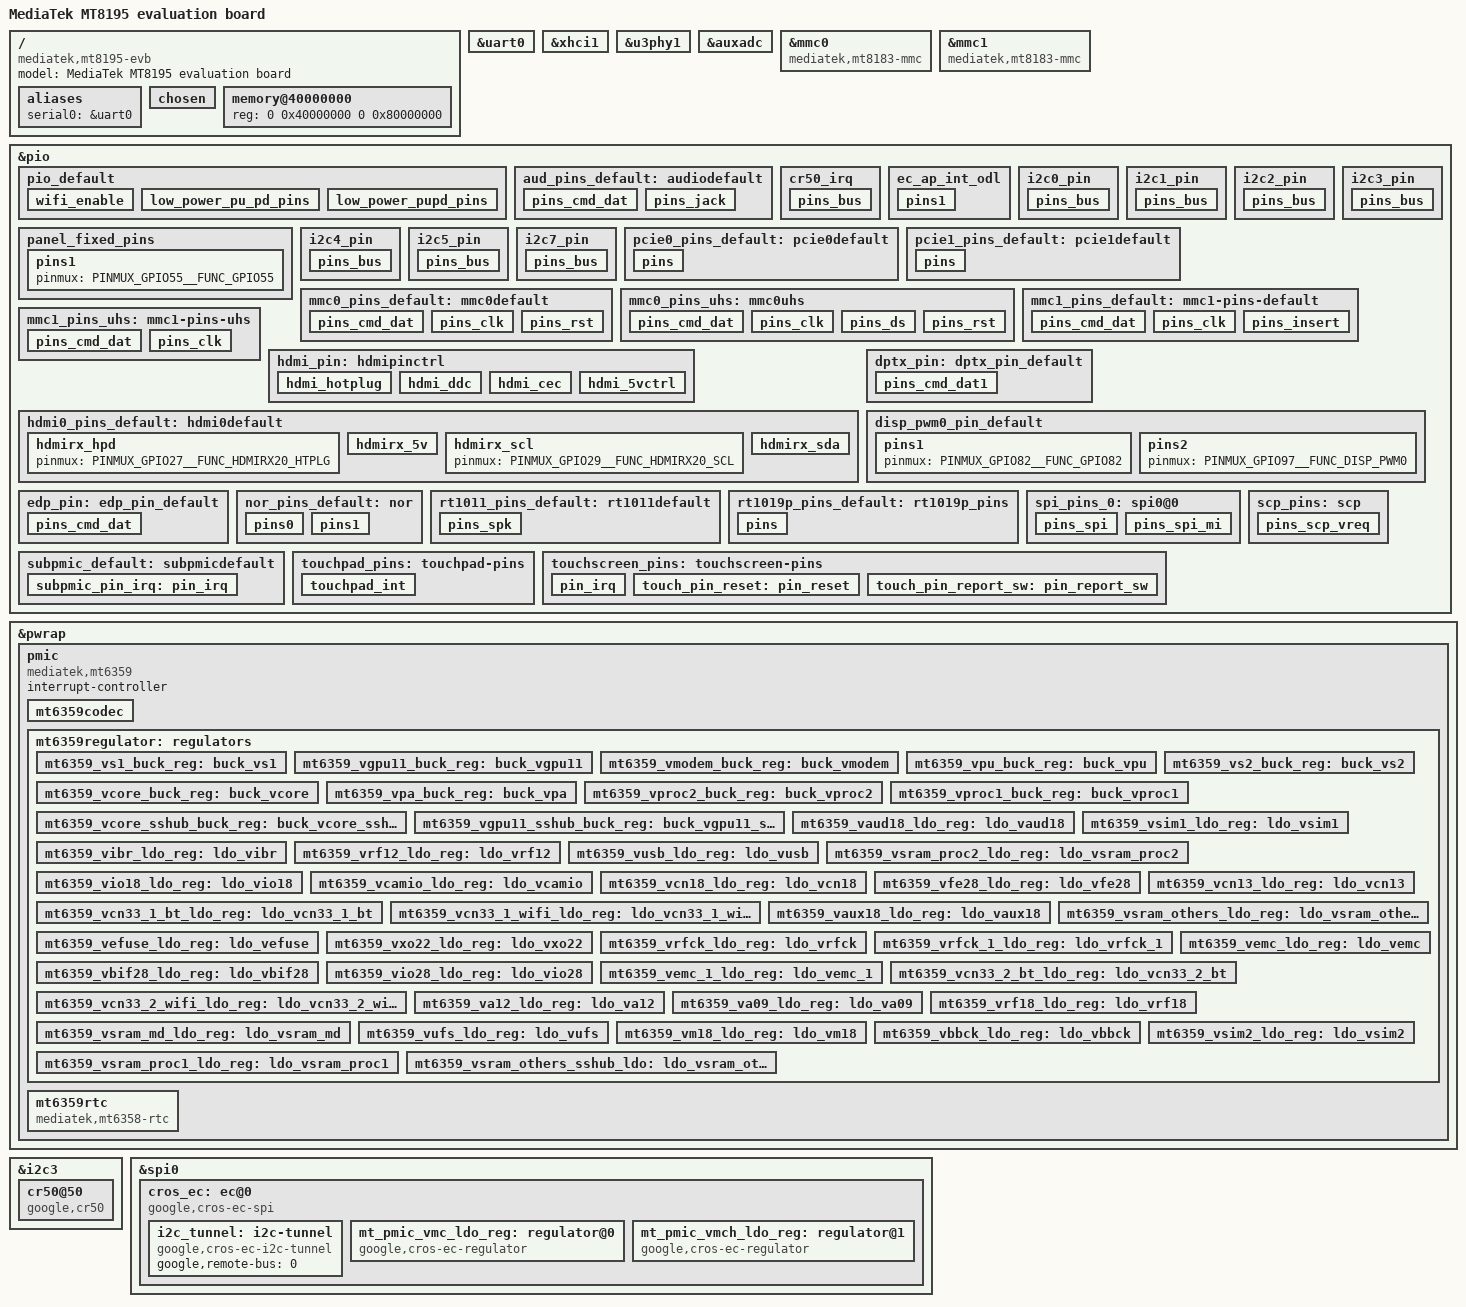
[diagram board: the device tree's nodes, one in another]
// SPDX-License-Identifier: (GPL-2.0 OR MIT)
/*
 * Copyright (C) 2021 MediaTek Inc.
 * Author: Seiya Wang <seiya.wang@mediatek.com>
 */
/dts-v1/;
#include <dt-bindings/gpio/gpio.h>
#include "mt8195.dtsi"

/ {
	model = "MediaTek MT8195 evaluation board";
	compatible = "mediatek,mt8195-evb", "mediatek,mt8195";

	aliases {
		serial0 = &uart0;
	};

	chosen {
		stdout-path = "serial0:115200n8";
		bootargs = "earlycon earlyprintk";
	};

	memory@40000000 {
		device_type = "memory";
		reg = <0 0x40000000 0 0x80000000>;
	};
};

&uart0 {
	status = "okay";
};

&xhci1 {
	status = "okay";
};

&u3phy1 {
	status = "okay";
};

&auxadc {
	status = "okay";
};



&mmc0 {
	/* Note: fixup for bad compatible on mt8195.dtsi */
	compatible = "mediatek,mt8183-mmc";
};

&mmc1 {
	/* Note: fixup for bad compatible on mt8195.dtsi */
	compatible = "mediatek,mt8183-mmc";
};

&mmc0 {
	status = "okay";
	pinctrl-names = "default", "state_uhs";
	pinctrl-0 = <&mmc0_pins_default>;
	pinctrl-1 = <&mmc0_pins_uhs>;
	bus-width = <8>;
	max-frequency = <200000000>;
	cap-mmc-highspeed;
	mmc-hs200-1_8v;
	mmc-hs400-1_8v;
	cap-mmc-hw-reset;
	no-sdio;
	no-sd;
	hs400-ds-delay = <0x14c11>;
	vmmc-supply = <&mt6359_vemc_1_ldo_reg>;
	vqmmc-supply = <&mt6359_vufs_ldo_reg>;
	non-removable;
};

&mmc1 {
	status = "okay";
	pinctrl-names = "default", "state_uhs";
	pinctrl-0 = <&mmc1_pins_default>;
	pinctrl-1 = <&mmc1_pins_uhs>;
	bus-width = <4>;
	max-frequency = <200000000>;
	cap-sd-highspeed;
	sd-uhs-sdr50;
	sd-uhs-sdr104;
	no-mmc;
	no-sdio;
	cd-gpios = <&pio 54 GPIO_ACTIVE_LOW>;
	vmmc-supply = <&mt_pmic_vmch_ldo_reg>;
	vqmmc-supply = <&mt_pmic_vmc_ldo_reg>;
};

&pio {
	pinctrl-names = "default";
	pinctrl-0 = <&pio_default>;
	/* 144 lines */
	gpio-line-names =
		"I2S_SPKR_MCLK",
		"I2S_SPKR_DATAIN",
		"I2S_SPKR_LRCK",
		"I2S_SPKR_BCLK",
		"EC_AP_INT_ODL",
		/*
		 * AP_FLASH_WP_L is crossystem ABI. Schematics
		 * call it AP_FLASH_WP_ODL.
		 */
		"AP_FLASH_WP_L",
		"TCHPAD_INT_ODL",
		"EDP_HPD_1V8",
		"AP_I2C_CAM_SDA",
		"AP_I2C_CAM_SCL",
		"AP_I2C_TCHPAD_SDA_1V8",
		"AP_I2C_TCHPAD_SCL_1V8",
		"AP_I2C_AUD_SDA",
		"AP_I2C_AUD_SCL",
		"AP_I2C_TPM_SDA_1V8",
		"AP_I2C_TPM_SCL_1V8",
		"AP_I2C_TCHSCR_SDA_1V8",
		"AP_I2C_TCHSCR_SCL_1V8",
		"EC_AP_HPD_OD",
		"",
		"PCIE_NVME_RST_L",
		"PCIE_NVME_CLKREQ_ODL",
		"PCIE_RST_1V8_L",
		"PCIE_CLKREQ_1V8_ODL",
		"PCIE_WAKE_1V8_ODL",
		"CLK_24M_CAM0",
		"CAM1_SEN_EN",
		"AP_I2C_PWR_SCL_1V8",
		"AP_I2C_PWR_SDA_1V8",
		"AP_I2C_MISC_SCL",
		"AP_I2C_MISC_SDA",
		"EN_PP5000_HDMI_X",
		"AP_HDMITX_HTPLG",
		"",
		"AP_HDMITX_SCL_1V8",
		"AP_HDMITX_SDA_1V8",
		"AP_RTC_CLK32K",
		"AP_EC_WATCHDOG_L",
		"SRCLKENA0",
		"SRCLKENA1",
		"PWRAP_SPI0_CS_L",
		"PWRAP_SPI0_CK",
		"PWRAP_SPI0_MOSI",
		"PWRAP_SPI0_MISO",
		"SPMI_SCL",
		"SPMI_SDA",
		"",
		"",
		"",
		"I2S_HP_DATAIN",
		"I2S_HP_MCLK",
		"I2S_HP_BCK",
		"I2S_HP_LRCK",
		"I2S_HP_DATAOUT",
		"SD_CD_ODL",
		"EN_PP3300_DISP_X",
		"TCHSCR_RST_1V8_L",
		"TCHSCR_REPORT_DISABLE",
		"EN_PP3300_WLAN_X",
		"BT_KILL_1V8_L",
		"I2S_SPKR_DATAOUT",
		"WIFI_KILL_1V8_L",
		"BEEP_ON",
		"SCP_I2C_SENSOR_SCL_1V8",
		"SCP_I2C_SENSOR_SDA_1V8",
		"",
		"",
		"",
		"",
		"AUD_CLK_MOSI",
		"AUD_SYNC_MOSI",
		"AUD_DAT_MOSI0",
		"AUD_DAT_MOSI1",
		"AUD_DAT_MISO0",
		"AUD_DAT_MISO1",
		"AUD_DAT_MISO2",
		"SCP_VREQ_VAO",
		"AP_SPI_GSC_TPM_CLK",
		"AP_SPI_GSC_TPM_MOSI",
		"AP_SPI_GSC_TPM_CS_L",
		"AP_SPI_GSC_TPM_MISO",
		"EN_PP1000_CAM_X",
		"AP_EDP_BKLTEN",
		"",
		"USB3_HUB_RST_L",
		"",
		"WLAN_ALERT_ODL",
		"EC_IN_RW_ODL",
		"GSC_AP_INT_ODL",
		"HP_INT_ODL",
		"CAM0_RST_L",
		"CAM1_RST_L",
		"TCHSCR_INT_1V8_L",
		"CAM1_DET_L",
		"RST_ALC1011_L",
		"",
		"",
		"BL_PWM_1V8",
		"UART_AP_TX_DBG_RX",
		"UART_DBG_TX_AP_RX",
		"EN_SPKR",
		"AP_EC_WARM_RST_REQ",
		"UART_SCP_TX_DBGCON_RX",
		"UART_DBGCON_TX_SCP_RX",
		"",
		"",
		"KPCOL0",
		"",
		"MT6315_GPU_INT",
		"MT6315_PROC_BC_INT",
		"SD_CMD",
		"SD_CLK",
		"SD_DAT0",
		"SD_DAT1",
		"SD_DAT2",
		"SD_DAT3",
		"EMMC_DAT7",
		"EMMC_DAT6",
		"EMMC_DAT5",
		"EMMC_DAT4",
		"EMMC_RSTB",
		"EMMC_CMD",
		"EMMC_CLK",
		"EMMC_DAT3",
		"EMMC_DAT2",
		"EMMC_DAT1",
		"EMMC_DAT0",
		"EMMC_DSL",
		"",
		"",
		"MT6360_INT_ODL",
		"SCP_JTAG0_TRSTN",
		"AP_SPI_EC_CS_L",
		"AP_SPI_EC_CLK",
		"AP_SPI_EC_MOSI",
		"AP_SPI_EC_MISO",
		"SCP_JTAG0_TMS",
		"SCP_JTAG0_TCK",
		"SCP_JTAG0_TDO",
		"SCP_JTAG0_TDI",
		"AP_SPI_FLASH_CS_L",
		"AP_SPI_FLASH_CLK",
		"AP_SPI_FLASH_MOSI",
		"AP_SPI_FLASH_MISO";

	pio_default: pio_default {
		wifi_enable {
			pinmux = <PINMUX_GPIO58__FUNC_GPIO58>;
			output-high;
			drive-strength = <MTK_DRIVE_14mA>;
		};
		low_power_pu_pd_pins {
			pinmux = <PINMUX_GPIO8__FUNC_GPIO8>,
				 <PINMUX_GPIO9__FUNC_GPIO9>,
				 <PINMUX_GPIO19__FUNC_GPIO19>,
				 <PINMUX_GPIO20__FUNC_GPIO20>,
				 <PINMUX_GPIO21__FUNC_GPIO21>,
				 <PINMUX_GPIO25__FUNC_GPIO25>,
				 <PINMUX_GPIO26__FUNC_GPIO26>,
				 <PINMUX_GPIO46__FUNC_GPIO46>,
				 <PINMUX_GPIO47__FUNC_GPIO47>,
				 <PINMUX_GPIO48__FUNC_GPIO48>,
				 <PINMUX_GPIO65__FUNC_GPIO65>,
				 <PINMUX_GPIO66__FUNC_GPIO66>,
				 <PINMUX_GPIO67__FUNC_GPIO67>,
				 <PINMUX_GPIO68__FUNC_GPIO68>,
				 <PINMUX_GPIO128__FUNC_GPIO128>,
				 <PINMUX_GPIO129__FUNC_GPIO129>;
			input-enable;
			bias-pull-down;
		};
		low_power_pupd_pins {
			pinmux = <PINMUX_GPIO77__FUNC_GPIO77>,
				 <PINMUX_GPIO78__FUNC_GPIO78>,
				 <PINMUX_GPIO79__FUNC_GPIO79>,
				 <PINMUX_GPIO80__FUNC_GPIO80>,
				 <PINMUX_GPIO83__FUNC_GPIO83>,
				 <PINMUX_GPIO85__FUNC_GPIO85>,
				 <PINMUX_GPIO90__FUNC_GPIO90>,
				 <PINMUX_GPIO91__FUNC_GPIO91>,
				 <PINMUX_GPIO93__FUNC_GPIO93>,
				 <PINMUX_GPIO94__FUNC_GPIO94>,
				 <PINMUX_GPIO95__FUNC_GPIO95>,
				 <PINMUX_GPIO96__FUNC_GPIO96>,
				 <PINMUX_GPIO104__FUNC_GPIO104>,
				 <PINMUX_GPIO105__FUNC_GPIO105>,
				 <PINMUX_GPIO107__FUNC_GPIO107>;
			input-enable;
			bias-pull-down = <MTK_PUPD_SET_R1R0_01>;
		};
	};
	aud_pins_default: audiodefault {
		pins_cmd_dat {
		    pinmux = <PINMUX_GPIO69__FUNC_AUD_CLK_MOSI>,
			     <PINMUX_GPIO70__FUNC_AUD_SYNC_MOSI>,
			     <PINMUX_GPIO71__FUNC_AUD_DAT_MOSI0>,
			     <PINMUX_GPIO72__FUNC_AUD_DAT_MOSI1>,
			     <PINMUX_GPIO73__FUNC_AUD_DAT_MISO0>,
			     <PINMUX_GPIO74__FUNC_AUD_DAT_MISO1>,
			     <PINMUX_GPIO75__FUNC_AUD_DAT_MISO2>,
			     <PINMUX_GPIO0__FUNC_TDMIN_MCK>,
			     <PINMUX_GPIO1__FUNC_TDMIN_DI>,
			     <PINMUX_GPIO2__FUNC_TDMIN_LRCK>,
			     <PINMUX_GPIO3__FUNC_TDMIN_BCK>,
			     <PINMUX_GPIO60__FUNC_I2SO2_D0>,
			     <PINMUX_GPIO49__FUNC_I2SIN_D0>,
			     <PINMUX_GPIO50__FUNC_I2SO1_MCK>,
			     <PINMUX_GPIO51__FUNC_I2SO1_BCK>,
			     <PINMUX_GPIO52__FUNC_I2SO1_WS>,
			     <PINMUX_GPIO53__FUNC_I2SO1_D0>;
		};
		pins_jack {
			pinmux = <PINMUX_GPIO89__FUNC_GPIO89>;
			input-enable;
			bias-pull-up = <MTK_PUPD_SET_R1R0_01>;
		};
	};
	cr50_irq: cr50_irq {
		pins_bus {
			pinmux = <PINMUX_GPIO88__FUNC_GPIO88>;
			input-enable;
		};
	};
	ec_ap_int_odl: ec_ap_int_odl {
		pins1 {
			pinmux = <PINMUX_GPIO4__FUNC_GPIO4>;
			input-enable;
			bias-pull-up = <MTK_PUPD_SET_R1R0_01>;
		};
	};
	i2c0_pin: i2c0_pin {
		pins_bus {
			pinmux = <PINMUX_GPIO8__FUNC_SDA0>,
				 <PINMUX_GPIO9__FUNC_SCL0>;
			bias-disable;
			mediatek,drive-strength-adv = <7>;
		};
	};
	i2c1_pin: i2c1_pin {
		pins_bus {
			pinmux = <PINMUX_GPIO10__FUNC_SDA1>,
				 <PINMUX_GPIO11__FUNC_SCL1>;
			bias-pull-up;
			mediatek,rsel = <7>;
			mediatek,drive-strength-adv = <7>;
		};
	};
	i2c2_pin: i2c2_pin {
		pins_bus {
			pinmux = <PINMUX_GPIO12__FUNC_SDA2>,
				 <PINMUX_GPIO13__FUNC_SCL2>;
			bias-disable;
			mediatek,drive-strength-adv = <7>;
		};
	};
	panel_fixed_pins: panel_fixed_pins {
		pins1 {
			pinmux = <PINMUX_GPIO55__FUNC_GPIO55>;
		};
	};
	i2c3_pin: i2c3_pin {
		pins_bus {
			pinmux = <PINMUX_GPIO14__FUNC_SDA3>,
				 <PINMUX_GPIO15__FUNC_SCL3>;
			bias-pull-up;
			mediatek,rsel = <7>;
			mediatek,drive-strength-adv = <7>;
		};
	};
	i2c4_pin: i2c4_pin {
		pins_bus {
			pinmux = <PINMUX_GPIO16__FUNC_SDA4>,
				 <PINMUX_GPIO17__FUNC_SCL4>;
			bias-pull-up;
			mediatek,rsel = <7>;
			mediatek,drive-strength-adv = <0>;
			drive-strength = <MTK_DRIVE_4mA>;
		};
	};
	i2c5_pin: i2c5_pin {
		pins_bus {
			pinmux = <PINMUX_GPIO29__FUNC_SCL5>,
				 <PINMUX_GPIO30__FUNC_SDA5>;
			bias-disable;
			mediatek,drive-strength-adv = <7>;
		};
	};
	i2c7_pin: i2c7_pin {
		pins_bus {
			pinmux = <PINMUX_GPIO27__FUNC_SCL7>,
				 <PINMUX_GPIO28__FUNC_SDA7>;
			bias-disable;
		};
	};
	pcie0_pins_default: pcie0default {
		pins {
			pinmux = <PINMUX_GPIO19__FUNC_WAKEN>,
				 <PINMUX_GPIO20__FUNC_PERSTN>,
				 <PINMUX_GPIO21__FUNC_CLKREQN>;
				 bias-pull-up;
		};
	};
	pcie1_pins_default: pcie1default {
		pins {
			pinmux = <PINMUX_GPIO22__FUNC_PERSTN_1>,
				 <PINMUX_GPIO23__FUNC_CLKREQN_1>,
				 <PINMUX_GPIO24__FUNC_WAKEN_1>;
				 bias-pull-up;
		};
	};
	mmc0_pins_default: mmc0default {
		pins_cmd_dat {
			pinmux = <PINMUX_GPIO126__FUNC_MSDC0_DAT0>,
				 <PINMUX_GPIO125__FUNC_MSDC0_DAT1>,
				 <PINMUX_GPIO124__FUNC_MSDC0_DAT2>,
				 <PINMUX_GPIO123__FUNC_MSDC0_DAT3>,
				 <PINMUX_GPIO119__FUNC_MSDC0_DAT4>,
				 <PINMUX_GPIO118__FUNC_MSDC0_DAT5>,
				 <PINMUX_GPIO117__FUNC_MSDC0_DAT6>,
				 <PINMUX_GPIO116__FUNC_MSDC0_DAT7>,
				 <PINMUX_GPIO121__FUNC_MSDC0_CMD>;
			input-enable;
			drive-strength = <MTK_DRIVE_6mA>;
			bias-pull-up = <MTK_PUPD_SET_R1R0_01>;
		};
		pins_clk {
			pinmux = <PINMUX_GPIO122__FUNC_MSDC0_CLK>;
			drive-strength = <MTK_DRIVE_6mA>;
			bias-pull-down = <MTK_PUPD_SET_R1R0_10>;
		};
		pins_rst {
			pinmux = <PINMUX_GPIO120__FUNC_MSDC0_RSTB>;
			drive-strength = <MTK_DRIVE_6mA>;
			bias-pull-up = <MTK_PUPD_SET_R1R0_01>;
		};
	};
	mmc0_pins_uhs: mmc0uhs{
		pins_cmd_dat {
			pinmux = <PINMUX_GPIO126__FUNC_MSDC0_DAT0>,
				 <PINMUX_GPIO125__FUNC_MSDC0_DAT1>,
				 <PINMUX_GPIO124__FUNC_MSDC0_DAT2>,
				 <PINMUX_GPIO123__FUNC_MSDC0_DAT3>,
				 <PINMUX_GPIO119__FUNC_MSDC0_DAT4>,
				 <PINMUX_GPIO118__FUNC_MSDC0_DAT5>,
				 <PINMUX_GPIO117__FUNC_MSDC0_DAT6>,
				 <PINMUX_GPIO116__FUNC_MSDC0_DAT7>,
				 <PINMUX_GPIO121__FUNC_MSDC0_CMD>;
			input-enable;
			drive-strength = <MTK_DRIVE_8mA>;
			bias-pull-up = <MTK_PUPD_SET_R1R0_01>;
		};
		pins_clk {
			pinmux = <PINMUX_GPIO122__FUNC_MSDC0_CLK>;
			drive-strength = <MTK_DRIVE_8mA>;
			bias-pull-down = <MTK_PUPD_SET_R1R0_10>;
		};
		pins_ds {
			pinmux = <PINMUX_GPIO127__FUNC_MSDC0_DSL>;
			drive-strength = <MTK_DRIVE_8mA>;
			bias-pull-down = <MTK_PUPD_SET_R1R0_10>;
		};
		pins_rst {
			pinmux = <PINMUX_GPIO120__FUNC_MSDC0_RSTB>;
			drive-strength = <MTK_DRIVE_8mA>;
			bias-pull-up = <MTK_PUPD_SET_R1R0_01>;
		};
	};
	mmc1_pins_default: mmc1-pins-default {
		pins_cmd_dat {
			pinmux = <PINMUX_GPIO110__FUNC_MSDC1_CMD>,
				 <PINMUX_GPIO112__FUNC_MSDC1_DAT0>,
				 <PINMUX_GPIO113__FUNC_MSDC1_DAT1>,
				 <PINMUX_GPIO114__FUNC_MSDC1_DAT2>,
				 <PINMUX_GPIO115__FUNC_MSDC1_DAT3>;
			input-enable;
			drive-strength = <MTK_DRIVE_8mA>;
			bias-pull-up = <MTK_PUPD_SET_R1R0_01>;
		};
		pins_clk {
			pinmux = <PINMUX_GPIO111__FUNC_MSDC1_CLK>;
			drive-strength = <MTK_DRIVE_8mA>;
			bias-pull-down = <MTK_PUPD_SET_R1R0_10>;
		};
		pins_insert {
			pinmux = <PINMUX_GPIO54__FUNC_GPIO54>;
			bias-pull-up;
		};
	};
	mmc1_pins_uhs: mmc1-pins-uhs {
		pins_cmd_dat {
			pinmux = <PINMUX_GPIO110__FUNC_MSDC1_CMD>,
				 <PINMUX_GPIO112__FUNC_MSDC1_DAT0>,
				 <PINMUX_GPIO113__FUNC_MSDC1_DAT1>,
				 <PINMUX_GPIO114__FUNC_MSDC1_DAT2>,
				 <PINMUX_GPIO115__FUNC_MSDC1_DAT3>;
			input-enable;
			drive-strength = <MTK_DRIVE_8mA>;
			bias-pull-up = <MTK_PUPD_SET_R1R0_01>;
		};
		pins_clk {
			pinmux = <PINMUX_GPIO111__FUNC_MSDC1_CLK>;
			drive-strength = <MTK_DRIVE_8mA>;
			bias-pull-down = <MTK_PUPD_SET_R1R0_10>;
		};
	};
	hdmi_pin: hdmipinctrl {
		hdmi_hotplug {
			pinmux = <PINMUX_GPIO32__FUNC_HDMITX20_HTPLG>;
			bias-disable;
			input-enable;
		};
		hdmi_ddc {
			pinmux = <PINMUX_GPIO34__FUNC_HDMITX20_SCL>,
				 <PINMUX_GPIO35__FUNC_HDMITX20_SDA>;
			mediatek,drive-strength-adv = <0>;
			drive-strength = <MTK_DRIVE_10mA>;
		};
		hdmi_cec {
			pinmux = <PINMUX_GPIO33__FUNC_HDMITX20_CEC>;
			bias-disable;
		};
		hdmi_5vctrl {
			pinmux = <PINMUX_GPIO31__FUNC_GPIO31>;
			slew-rate = <1>;
			output-high;
		};
	};
	hdmi0_pins_default: hdmi0default {
		hdmirx_hpd {
			pinmux = <PINMUX_GPIO27__FUNC_HDMIRX20_HTPLG>;
		};
		hdmirx_5v {
			pinmux = <PINMUX_GPIO28__FUNC_HDMIRX20_PWR5V>;
			bias-disable;
		};
		hdmirx_scl {
			pinmux = <PINMUX_GPIO29__FUNC_HDMIRX20_SCL>;
		};
		hdmirx_sda {
			pinmux = <PINMUX_GPIO30__FUNC_HDMIRX20_SDA>;
			mediatek,drive-strength-adv = <0>;
			drive-strength = <MTK_DRIVE_10mA>;
		};
	};
	dptx_pin: dptx_pin_default {
		pins_cmd_dat1 {
			pinmux = <PINMUX_GPIO18__FUNC_DP_TX_HPD>;
			bias-pull-up;
		};
	};
	disp_pwm0_pin_default: disp_pwm0_pin_default {
		pins1 {
			pinmux = <PINMUX_GPIO82__FUNC_GPIO82>;
		};
		pins2 {
			pinmux = <PINMUX_GPIO97__FUNC_DISP_PWM0>;
		};
	};
	edp_pin: edp_pin_default {
		pins_cmd_dat {
			pinmux = <PINMUX_GPIO7__FUNC_EDP_TX_HPD>;
			bias-pull-up;
		};
	};
	nor_pins_default: nor {
		pins0 {
			pinmux = <PINMUX_GPIO142__FUNC_SPINOR_IO0>,
				 <PINMUX_GPIO141__FUNC_SPINOR_CK>,
				 <PINMUX_GPIO143__FUNC_SPINOR_IO1>;
			drive-strength = <MTK_DRIVE_6mA>;
			bias-pull-down;
		};
		pins1 {
			pinmux = <PINMUX_GPIO140__FUNC_SPINOR_CS>;
			drive-strength = <MTK_DRIVE_6mA>;
			bias-pull-up;
		};
	};
	rt1011_pins_default: rt1011default {
		pins_spk {
			pinmux = <PINMUX_GPIO94__FUNC_GPIO94>,
			     <PINMUX_GPIO100__FUNC_GPIO100>;
			output-high;
		};
	};
	rt1019p_pins_default: rt1019p_pins {
		pins {
			pinmux = <PINMUX_GPIO100__FUNC_GPIO100>;
			output-low;
		};
	};
	spi_pins_0: spi0@0 {
		pins_spi {
			pinmux = <PINMUX_GPIO132__FUNC_SPIM0_CSB>,
				 <PINMUX_GPIO134__FUNC_SPIM0_MO>,
				 <PINMUX_GPIO133__FUNC_SPIM0_CLK>;
			bias-disable;
		};
		pins_spi_mi {
			pinmux = <PINMUX_GPIO135__FUNC_SPIM0_MI>;
			bias-pull-down;
		};
	};
	subpmic_default: subpmicdefault {
		subpmic_pin_irq: pin_irq {
			pinmux = <PINMUX_GPIO130__FUNC_GPIO130>;
			input-enable;
			bias-pull-up;
		};
	};
	touchpad_pins: touchpad-pins {
		touchpad_int {
			pinmux = <PINMUX_GPIO6__FUNC_GPIO6>;
			input-enable;
			bias-pull-up;
		};
	};
	touchscreen_pins: touchscreen-pins {
		pin_irq {
			pinmux = <PINMUX_GPIO92__FUNC_GPIO92>;
			input-enable;
			bias-pull-up = <MTK_PUPD_SET_R1R0_01>;
		};
		touch_pin_reset: pin_reset {
			pinmux = <PINMUX_GPIO56__FUNC_GPIO56>;
			output-high;
		};
		touch_pin_report_sw: pin_report_sw {
			pinmux = <PINMUX_GPIO57__FUNC_GPIO57>;
			output-low;
		};
	};
	scp_pins: scp {
		pins_scp_vreq {
			pinmux = <PINMUX_GPIO76__FUNC_SCP_VREQ_VAO>;
			bias-disable;
			input-enable;
		};
	};
};






&pwrap {
	pmic: pmic {
		compatible = "mediatek,mt6359";
		interrupt-controller;
		#interrupt-cells = <2>;
		mt6359codec: mt6359codec {
		};
		mt6359regulator: regulators {
			mt6359_vs1_buck_reg: buck_vs1 {
				regulator-name = "vs1";
				regulator-min-microvolt = <800000>;
				regulator-max-microvolt = <2200000>;
				regulator-enable-ramp-delay = <0>;
				regulator-always-on;
			};
			mt6359_vgpu11_buck_reg: buck_vgpu11 {
				regulator-name = "vgpu11";
				regulator-min-microvolt = <400000>;
				regulator-max-microvolt = <1193750>;
				regulator-ramp-delay = <5000>;
				regulator-enable-ramp-delay = <200>;
				regulator-allowed-modes = <0 1 2>;
			};
			mt6359_vmodem_buck_reg: buck_vmodem {
				regulator-name = "vmodem";
				regulator-min-microvolt = <400000>;
				regulator-max-microvolt = <1100000>;
				regulator-ramp-delay = <10760>;
				regulator-enable-ramp-delay = <200>;
			};
			mt6359_vpu_buck_reg: buck_vpu {
				regulator-name = "vpu";
				regulator-min-microvolt = <400000>;
				regulator-max-microvolt = <1193750>;
				regulator-ramp-delay = <5000>;
				regulator-enable-ramp-delay = <200>;
				regulator-allowed-modes = <0 1 2>;
			};
			mt6359_vcore_buck_reg: buck_vcore {
				regulator-name = "vcore";
				regulator-min-microvolt = <400000>;
				regulator-max-microvolt = <1300000>;
				regulator-ramp-delay = <5000>;
				regulator-enable-ramp-delay = <200>;
				regulator-allowed-modes = <0 1 2>;
			};
			mt6359_vs2_buck_reg: buck_vs2 {
				regulator-name = "vs2";
				regulator-min-microvolt = <800000>;
				regulator-max-microvolt = <1600000>;
				regulator-enable-ramp-delay = <0>;
				regulator-always-on;
			};
			mt6359_vpa_buck_reg: buck_vpa {
				regulator-name = "vpa";
				regulator-min-microvolt = <500000>;
				regulator-max-microvolt = <3650000>;
				regulator-enable-ramp-delay = <300>;
			};
			mt6359_vproc2_buck_reg: buck_vproc2 {
				regulator-name = "vproc2";
				regulator-min-microvolt = <400000>;
				regulator-max-microvolt = <1193750>;
				regulator-ramp-delay = <7500>;
				regulator-enable-ramp-delay = <200>;
				regulator-allowed-modes = <0 1 2>;
			};
			mt6359_vproc1_buck_reg: buck_vproc1 {
				regulator-name = "vproc1";
				regulator-min-microvolt = <400000>;
				regulator-max-microvolt = <1193750>;
				regulator-ramp-delay = <7500>;
				regulator-enable-ramp-delay = <200>;
				regulator-allowed-modes = <0 1 2>;
			};
			mt6359_vcore_sshub_buck_reg: buck_vcore_sshub {
				regulator-name = "vcore_sshub";
				regulator-min-microvolt = <400000>;
				regulator-max-microvolt = <1193750>;
			};
			mt6359_vgpu11_sshub_buck_reg: buck_vgpu11_sshub {
				regulator-name = "vgpu11_sshub";
				regulator-min-microvolt = <400000>;
				regulator-max-microvolt = <1193750>;
			};
			mt6359_vaud18_ldo_reg: ldo_vaud18 {
				regulator-name = "vaud18";
				regulator-min-microvolt = <1800000>;
				regulator-max-microvolt = <1800000>;
				regulator-enable-ramp-delay = <240>;
			};
			mt6359_vsim1_ldo_reg: ldo_vsim1 {
				regulator-name = "vsim1";
				regulator-min-microvolt = <1700000>;
				regulator-max-microvolt = <3100000>;
			};
			mt6359_vibr_ldo_reg: ldo_vibr {
				regulator-name = "vibr";
				regulator-min-microvolt = <1200000>;
				regulator-max-microvolt = <3300000>;
			};
			mt6359_vrf12_ldo_reg: ldo_vrf12 {
				regulator-name = "vrf12";
				regulator-min-microvolt = <1100000>;
				regulator-max-microvolt = <1300000>;
			};
			mt6359_vusb_ldo_reg: ldo_vusb {
				regulator-name = "vusb";
				regulator-min-microvolt = <3000000>;
				regulator-max-microvolt = <3000000>;
				regulator-enable-ramp-delay = <960>;
				regulator-always-on;
			};
			mt6359_vsram_proc2_ldo_reg: ldo_vsram_proc2 {
				regulator-name = "vsram_proc2";
				regulator-min-microvolt = <500000>;
				regulator-max-microvolt = <1293750>;
				regulator-ramp-delay = <7500>;
				regulator-enable-ramp-delay = <240>;
				regulator-always-on;
			};
			mt6359_vio18_ldo_reg: ldo_vio18 {
				regulator-name = "vio18";
				regulator-min-microvolt = <1700000>;
				regulator-max-microvolt = <1900000>;
				regulator-enable-ramp-delay = <960>;
				regulator-always-on;
			};
			mt6359_vcamio_ldo_reg: ldo_vcamio {
				regulator-name = "vcamio";
				regulator-min-microvolt = <1700000>;
				regulator-max-microvolt = <1900000>;
			};
			mt6359_vcn18_ldo_reg: ldo_vcn18 {
				regulator-name = "vcn18";
				regulator-min-microvolt = <1800000>;
				regulator-max-microvolt = <1800000>;
				regulator-enable-ramp-delay = <240>;
			};
			mt6359_vfe28_ldo_reg: ldo_vfe28 {
				regulator-name = "vfe28";
				regulator-min-microvolt = <2800000>;
				regulator-max-microvolt = <2800000>;
				regulator-enable-ramp-delay = <120>;
			};
			mt6359_vcn13_ldo_reg: ldo_vcn13 {
				regulator-name = "vcn13";
				regulator-min-microvolt = <900000>;
				regulator-max-microvolt = <1300000>;
			};
			mt6359_vcn33_1_bt_ldo_reg: ldo_vcn33_1_bt {
				regulator-name = "vcn33_1_bt";
				regulator-min-microvolt = <2800000>;
				regulator-max-microvolt = <3500000>;
			};
			mt6359_vcn33_1_wifi_ldo_reg: ldo_vcn33_1_wifi {
				regulator-name = "vcn33_1_wifi";
				regulator-min-microvolt = <2800000>;
				regulator-max-microvolt = <3500000>;
			};
			mt6359_vaux18_ldo_reg: ldo_vaux18 {
				regulator-name = "vaux18";
				regulator-min-microvolt = <1800000>;
				regulator-max-microvolt = <1800000>;
				regulator-enable-ramp-delay = <240>;
				regulator-always-on;
			};
			mt6359_vsram_others_ldo_reg: ldo_vsram_others {
				regulator-name = "vsram_others";
				regulator-min-microvolt = <500000>;
				regulator-max-microvolt = <1293750>;
				regulator-ramp-delay = <5000>;
				regulator-enable-ramp-delay = <240>;
			};
			mt6359_vefuse_ldo_reg: ldo_vefuse {
				regulator-name = "vefuse";
				regulator-min-microvolt = <1700000>;
				regulator-max-microvolt = <2000000>;
			};
			mt6359_vxo22_ldo_reg: ldo_vxo22 {
				regulator-name = "vxo22";
				regulator-min-microvolt = <1800000>;
				regulator-max-microvolt = <2200000>;
				regulator-always-on;
			};
			mt6359_vrfck_ldo_reg: ldo_vrfck {
				regulator-name = "vrfck";
				regulator-min-microvolt = <1500000>;
				regulator-max-microvolt = <1700000>;
			};
			mt6359_vrfck_1_ldo_reg: ldo_vrfck_1 {
				regulator-name = "vrfck";
				regulator-min-microvolt = <1240000>;
				regulator-max-microvolt = <1600000>;
			};
			mt6359_vbif28_ldo_reg: ldo_vbif28 {
				regulator-name = "vbif28";
				regulator-min-microvolt = <2800000>;
				regulator-max-microvolt = <2800000>;
				regulator-enable-ramp-delay = <240>;
			};
			mt6359_vio28_ldo_reg: ldo_vio28 {
				regulator-name = "vio28";
				regulator-min-microvolt = <2800000>;
				regulator-max-microvolt = <3300000>;
				regulator-always-on;
			};
			mt6359_vemc_ldo_reg: ldo_vemc {
				regulator-name = "vemc";
				regulator-min-microvolt = <2900000>;
				regulator-max-microvolt = <3300000>;
			};
			mt6359_vemc_1_ldo_reg: ldo_vemc_1 {
				regulator-name = "vemc";
				regulator-min-microvolt = <2500000>;
				regulator-max-microvolt = <3300000>;
			};
			mt6359_vcn33_2_bt_ldo_reg: ldo_vcn33_2_bt {
				regulator-name = "vcn33_2_bt";
				regulator-min-microvolt = <2800000>;
				regulator-max-microvolt = <3500000>;
			};
			mt6359_vcn33_2_wifi_ldo_reg: ldo_vcn33_2_wifi {
				regulator-name = "vcn33_2_wifi";
				regulator-min-microvolt = <2800000>;
				regulator-max-microvolt = <3500000>;
			};
			mt6359_va12_ldo_reg: ldo_va12 {
				regulator-name = "va12";
				regulator-min-microvolt = <1200000>;
				regulator-max-microvolt = <1300000>;
				regulator-always-on;
			};
			mt6359_va09_ldo_reg: ldo_va09 {
				regulator-name = "va09";
				regulator-min-microvolt = <800000>;
				regulator-max-microvolt = <1200000>;
			};
			mt6359_vrf18_ldo_reg: ldo_vrf18 {
				regulator-name = "vrf18";
				regulator-min-microvolt = <1700000>;
				regulator-max-microvolt = <1810000>;
			};
			mt6359_vsram_md_ldo_reg: ldo_vsram_md {
				regulator-name = "vsram_md";
				regulator-min-microvolt = <500000>;
				regulator-max-microvolt = <1293750>;
				regulator-ramp-delay = <10760>;
				regulator-enable-ramp-delay = <240>;
			};
			mt6359_vufs_ldo_reg: ldo_vufs {
				regulator-name = "vufs";
				regulator-min-microvolt = <1700000>;
				regulator-max-microvolt = <1900000>;
			};
			mt6359_vm18_ldo_reg: ldo_vm18 {
				regulator-name = "vm18";
				regulator-min-microvolt = <1700000>;
				regulator-max-microvolt = <1900000>;
				regulator-always-on;
			};
			mt6359_vbbck_ldo_reg: ldo_vbbck {
				regulator-name = "vbbck";
				regulator-min-microvolt = <1100000>;
				regulator-max-microvolt = <1200000>;
			};
			mt6359_vsram_proc1_ldo_reg: ldo_vsram_proc1 {
				regulator-name = "vsram_proc1";
				regulator-min-microvolt = <500000>;
				regulator-max-microvolt = <1293750>;
				regulator-ramp-delay = <7500>;
				regulator-enable-ramp-delay = <240>;
				regulator-always-on;
			};
			mt6359_vsim2_ldo_reg: ldo_vsim2 {
				regulator-name = "vsim2";
				regulator-min-microvolt = <1700000>;
				regulator-max-microvolt = <3100000>;
			};
			mt6359_vsram_others_sshub_ldo: ldo_vsram_others_sshub {
				regulator-name = "vsram_others_sshub";
				regulator-min-microvolt = <500000>;
				regulator-max-microvolt = <1293750>;
			};
		};
		mt6359rtc: mt6359rtc {
			compatible = "mediatek,mt6358-rtc";
		};
	};
};


&mt6359codec {
	mediatek,dmic-mode = <1>; /* one-wire */
	mediatek,mic-type-0 = <2>; /* DMIC */
};
&mt6359_vgpu11_sshub_buck_reg {
	regulator-always-on;
	regulator-min-microvolt = <550000>;
	regulator-max-microvolt = <550000>;
};
/* for CORE */
&mt6359_vgpu11_buck_reg {
	regulator-always-on;
};
/* for CORE SRAM */
&mt6359_vpu_buck_reg {
	regulator-always-on;
};
/* for CPU-L */
&mt6359_vcore_buck_reg {
	regulator-always-on;
};
&mt6359_vrf12_ldo_reg {
	regulator-always-on;
};
&mt6359_vufs_ldo_reg {
	regulator-always-on;
};


&i2c3 {
	status = "okay";
	clock-frequency = <400000>;
	pinctrl-names = "default";
	pinctrl-0 = <&i2c3_pin>;
	cr50@50 {
		compatible = "google,cr50";
		reg = <0x50>;
		interrupt-parent = <&pio>;
		interrupts = <88 IRQ_TYPE_EDGE_FALLING>;
		pinctrl-names = "default";
		pinctrl-0 = <&cr50_irq>;
	};
};

&spi0 {
	pinctrl-names = "default";
	pinctrl-0 = <&spi_pins_0>;
	mediatek,pad-select = <0>;
	status = "okay";
	cros_ec: ec@0 {
		compatible = "google,cros-ec-spi";
		reg = <0>;
		spi-max-frequency = <3000000>;
		interrupt-parent = <&pio>;
		interrupts = <4 IRQ_TYPE_LEVEL_LOW>;
		pinctrl-names = "default";
		pinctrl-0 = <&ec_ap_int_odl>;
		#address-cells = <1>;
		#size-cells = <0>;
		i2c_tunnel: i2c-tunnel {
			compatible = "google,cros-ec-i2c-tunnel";
			google,remote-bus = <0>;
			#address-cells = <1>;
			#size-cells = <0>;
		};
	};
};

&cros_ec {
	mt_pmic_vmc_ldo_reg: regulator@0 {
		compatible = "google,cros-ec-regulator";
		regulator-min-microvolt = <1200000>;
		regulator-max-microvolt = <3600000>;
		reg = <0>;
	};
	mt_pmic_vmch_ldo_reg: regulator@1 {
		compatible = "google,cros-ec-regulator";
		regulator-min-microvolt = <2700000>;
		regulator-max-microvolt = <3600000>;
		reg = <1>;
	};
};

#include <arm/cros-ec-keyboard.dtsi>
#include <arm/cros-ec-sbs.dtsi>
